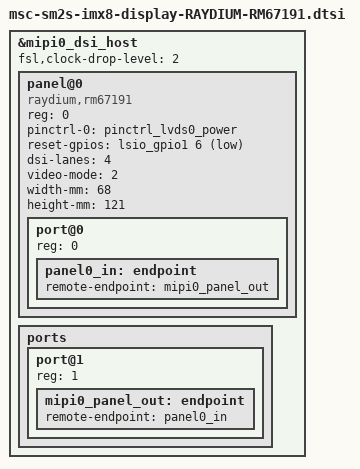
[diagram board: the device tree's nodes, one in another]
/** @file      msc-sm2s-imx8-display-RAYDIUM-RM67191.dtsi

    @copyright Copyright (C) 2021 by MSC Technologies GmbH
    SPDX-License Identifier: GPL-2.0-or-later

    @author    Markus Pietrek

    @details   For DSI RAYDIUM-RM67191
	           GPIO 1.05/LCD0_BKLT_EN is not used on raydium, therefore we don't have a regulator.
*/

#include <dt-bindings/gpio/gpio.h>
#include <dt-bindings/pinctrl/pads-imx8qm-pintool-compatible.h>

/dts-v1/;
/plugin/;

/*
#define HAS_DSI
*/

#include "msc-sm2s-imx8-display.dtsi"

/ {
	fragment@2001 {
		target = <&mipi0_dsi_host>;
		__overlay__ {
			#address-cells = <1>;
			#size-cells = <0>;
			status = "okay";
			fsl,clock-drop-level = <2>;

			panel@0 {
				#address-cells = <1>;
				#size-cells = <0>;

				compatible = "raydium,rm67191";
				reg = <0>;
				pinctrl-0 = <&pinctrl_lvds0_power>;
				pinctrl-names = "default";
				reset-gpios = <&lsio_gpio1 6 GPIO_ACTIVE_LOW>;
				dsi-lanes = <4>;
				video-mode = <2>;
				width-mm = <68>;
				height-mm = <121>;

				port@0 {
					reg = <0>;
					panel0_in: endpoint {
						remote-endpoint = <&mipi0_panel_out>;
					};
				};
			};

			ports {
				#address-cells = <1>;
				#size-cells = <0>;
				/delete-node/ port@1;
				port@1 {
					reg = <1>;
					mipi0_panel_out: endpoint {
						remote-endpoint = <&panel0_in>;
					};
				};
			};
		};
	};
};
